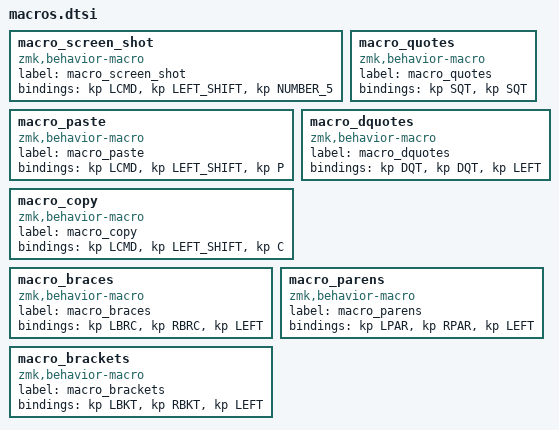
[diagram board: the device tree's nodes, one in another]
macro_screen_shot: macro_screen_shot{
compatible = "zmk,behavior-macro";
label = "macro_screen_shot";
#binding-cells = <0>;
bindings = <&kp LCMD>, <&kp LEFT_SHIFT>, <&kp NUMBER_5>;
};
macro_paste: macro_paste{
compatible = "zmk,behavior-macro";
label = "macro_paste";
#binding-cells = <0>;
bindings = <&kp LCMD>, <&kp LEFT_SHIFT>, <&kp P>;
};
macro_copy: macro_copy{
compatible = "zmk,behavior-macro";
label = "macro_copy";
#binding-cells = <0>;
bindings = <&kp LCMD>, <&kp LEFT_SHIFT>, <&kp C>;
};
macro_quotes: macro_quotes{
compatible = "zmk,behavior-macro";
label = "macro_quotes";
#binding-cells = <0>;
bindings = <&kp SQT>, <&kp SQT>;
};
macro_dquotes: macro_dquotes{
compatible = "zmk,behavior-macro";
label = "macro_dquotes";
#binding-cells = <0>;
bindings = <&kp DQT>, <&kp DQT>, <&kp LEFT>;
};
macro_braces: macro_braces{
compatible = "zmk,behavior-macro";
label = "macro_braces";
#binding-cells = <0>;
bindings = <&kp LBRC>, <&kp RBRC>, <&kp LEFT>;
};
macro_parens: macro_parens{
compatible = "zmk,behavior-macro";
label = "macro_parens";
#binding-cells = <0>;
bindings = <&kp LPAR>, <&kp RPAR>, <&kp LEFT>;
};
macro_brackets: macro_brackets{
compatible = "zmk,behavior-macro";
label = "macro_brackets";
#binding-cells = <0>;
bindings = <&kp LBKT>, <&kp RBKT>, <&kp LEFT>;
};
